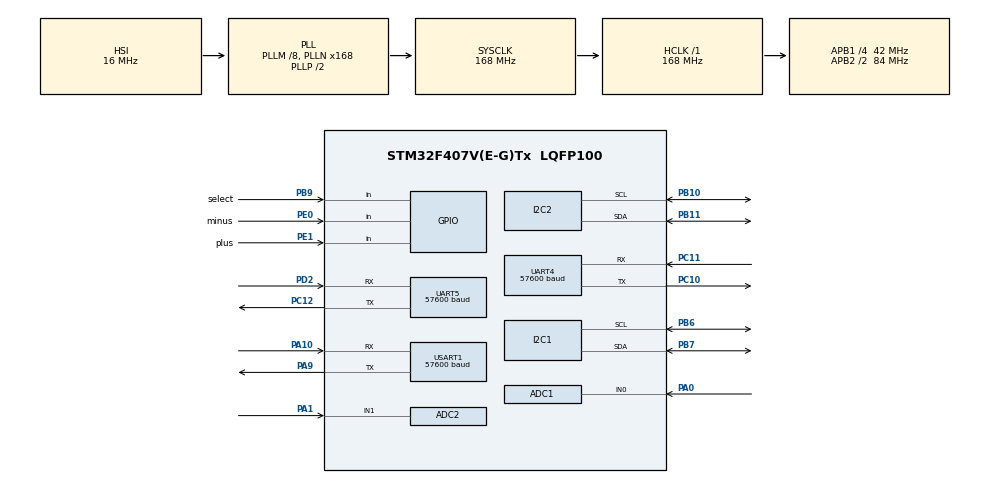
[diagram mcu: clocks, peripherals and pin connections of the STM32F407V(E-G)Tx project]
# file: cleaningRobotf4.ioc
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Mcu.Family=STM32F4
PH0-OSC_IN.Signal=RCC_OSC_IN
RCC.CortexFreq_Value=168000000
PB10.Mode=I2C
ADC1.ContinuousConvMode=ENABLE
ADC2.Channel-0\#ChannelRegularConversion=ADC_CHANNEL_1
USART1.BaudRate=57600
PC10.Signal=UART4_TX
PC12.Signal=UART5_TX
PB11.Signal=I2C2_SDA
RCC.SYSCLKSource=RCC_SYSCLKSOURCE_PLLCLK
ProjectManager.StackSize=0x400
VP_FREERTOS_VS_CMSIS_V2.Mode=CMSIS_V2
NVIC.UART5_IRQn=true\:5\:0\:false\:false\:true\:true\:true\:true
UART4.BaudRate=57600
RCC.HCLKFreq_Value=168000000
RCC.APB2TimFreq_Value=168000000
PB6.Signal=I2C1_SCL
PB6.Mode=I2C
PE1.Signal=GPIO_Input
RCC.AHBFreq_Value=168000000
PH0-OSC_IN.Mode=HSE-External-Oscillator
ADC1.Channel-0\#ChannelRegularConversion=ADC_CHANNEL_VREFINT
RCC.HSE_VALUE=8000000
ADC1.ScanConvMode=ENABLE
VP_ADC1_Vref_Input.Mode=IN-Vrefint
PA14.Mode=Serial_Wire
VP_SYS_VS_tim1.Mode=TIM1
NVIC.TIM2_IRQn=true\:5\:0\:false\:false\:true\:true\:true\:true
PB7.Signal=I2C1_SDA
SH.ADCx_IN0.0=ADC1_IN0,IN0
ADC1.SamplingTime-0\#ChannelRegularConversion=ADC_SAMPLETIME_3CYCLES
PH1-OSC_OUT.Mode=HSE-External-Oscillator
PB9.Signal=GPIO_Input
Mcu.Package=LQFP100
TIM2.Prescaler=1
NVIC.TimeBase=TIM1_UP_TIM10_IRQn
NVIC.TimeBaseIP=TIM1
PA10.Signal=USART1_RX
PB9.GPIO_PuPd=GPIO_PULLUP
ADC2.SamplingTime-0\#ChannelRegularConversion=ADC_SAMPLETIME_15CYCLES
PC11.Mode=Asynchronous
PE0.GPIO_Label=minus
RCC.APB2CLKDivider=RCC_HCLK_DIV2
SH.ADCx_IN1.0=ADC2_IN1,IN1
RCC.APB1TimFreq_Value=84000000
UART5.BaudRate=57600
ADC2.Rank-0\#ChannelRegularConversion=1
NVIC.UART4_IRQn=true\:5\:0\:false\:false\:true\:true\:true\:true
PE0.GPIO_PuPd=GPIO_PULLUP
ADC2.ClockPrescaler=ADC_CLOCK_SYNC_PCLK_DIV8
FREERTOS.Tasks01=defaultTask,24,128,StartDefaultTask,Default,NULL,Dynamic,NULL,NULL
ADC1.Rank-0\#ChannelRegularConversion=1
PB9.GPIO_Label=select
PA10.Mode=Asynchronous
PC11.Signal=UART4_RX
PC10.Mode=Asynchronous
PE1.GPIO_PuPd=GPIO_PULLUP
UART5.VirtualMode=Asynchronous
RCC.APB1CLKDivider=RCC_HCLK_DIV4
UART4.VirtualMode=Asynchronous
PA0-WKUP.Signal=ADCx_IN0
PA13.Signal=SYS_JTMS-SWDIO
PA9.Mode=Asynchronous
PB11.Mode=I2C
ADC2.ContinuousConvMode=ENABLE
ProjectManager.TargetToolchain=STM32CubeIDE
PA9.Signal=USART1_TX
ADC1.Channel-1\#ChannelRegularConversion=ADC_CHANNEL_0
RCC.LSE_VALUE=32768
PA1.Signal=ADCx_IN1
PB10.Signal=I2C2_SCL
PD2.Mode=Asynchronous
PC12.Mode=Asynchronous
board=custom
RCC.VCOOutputFreq_Value=336000000
PE1.GPIO_Label=plus
RCC.APB2Freq_Value=84000000
VP_TIM2_VS_ClockSourceINT.Mode=Internal
PH1-OSC_OUT.Signal=RCC_OSC_OUT
TIM2.Period=41999
ADC1.NbrOfConversion=2
PA13.Mode=Serial_Wire
Mcu.Name=STM32F407V(E-G)Tx
PE0.Signal=GPIO_Input
RCC.48MHZClocksFreq_Value=84000000
ADC1.SamplingTime-1\#ChannelRegularConversion=ADC_SAMPLETIME_15CYCLES
RCC.SYSCLKFreq_VALUE=168000000
ADC1.master=1
ADC2.NbrOfConversionFlag=1
USART1.VirtualMode=VM_ASYNC
ADC1.Rank-1\#ChannelRegularConversion=2
PB7.Mode=I2C
PA14.Signal=SYS_JTCK-SWCLK
ProjectManager.HeapSize=0x200
NVIC.TIM1_UP_TIM10_IRQn=true\:0\:0\:false\:false\:true\:false\:false\:true
RCC.HSI_VALUE=16000000
NVIC.PriorityGroup=NVIC_PRIORITYGROUP_4
ADC1.NbrOfConversionFlag=1
RCC.PLLM=8
RCC.PLLN=168
PD2.Signal=UART5_RX
RCC.APB1Freq_Value=42000000
ADC1.ClockPrescaler=ADC_CLOCK_SYNC_PCLK_DIV8

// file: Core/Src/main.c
/* USER CODE BEGIN Header */
/**
  ******************************************************************************
  * @file           : main.c
  * @brief          : Main program body
  ******************************************************************************
  * @attention
  *
  * <h2><center>&copy; Copyright (c) 2021 STMicroelectronics.
  * All rights reserved.</center></h2>
  *
  * This software component is licensed by ST under BSD 3-Clause license,
  * the "License"; You may not use this file except in compliance with the
  * License. You may obtain a copy of the License at:
  *                        opensource.org/licenses/BSD-3-Clause
  *
  ******************************************************************************
  */
/* USER CODE END Header */
#include "main.h"
#include "cmsis_os.h"

/* USER CODE BEGIN Includes */

#include "taskManagerInterface.h"
/* USER CODE END Includes */

ADC_HandleTypeDef hadc1;
ADC_HandleTypeDef hadc2;

I2C_HandleTypeDef hi2c1;
I2C_HandleTypeDef hi2c2;

TIM_HandleTypeDef htim2;

UART_HandleTypeDef huart4;
UART_HandleTypeDef huart5;
UART_HandleTypeDef huart1;

/* Definitions for defaultTask */
osThreadId_t defaultTaskHandle;
const osThreadAttr_t defaultTask_attributes = {
  .name = "defaultTask",
  .priority = (osPriority_t) osPriorityNormal,
  .stack_size = 128 * 4
};

void SystemClock_Config(void);
static void MX_GPIO_Init(void);
static void MX_ADC1_Init(void);
static void MX_ADC2_Init(void);
static void MX_I2C1_Init(void);
static void MX_TIM2_Init(void);
static void MX_UART4_Init(void);
static void MX_UART5_Init(void);
static void MX_USART1_UART_Init(void);
static void MX_I2C2_Init(void);
void StartDefaultTask(void *argument);

int main(void)
{

  /* MCU Configuration--------------------------------------------------------*/

  /* Reset of all peripherals, Initializes the Flash interface and the Systick. */
  HAL_Init();

  /* Configure the system clock */
  SystemClock_Config();

  /* Initialize all configured peripherals */
  MX_GPIO_Init();
  MX_ADC1_Init();
  MX_ADC2_Init();
  MX_I2C1_Init();
  MX_TIM2_Init();
  MX_UART4_Init();
  MX_UART5_Init();
  MX_USART1_UART_Init();
  MX_I2C2_Init();
  /* USER CODE BEGIN 2 */
  tasks_init();
  /* USER CODE END 2 */

  /* Init scheduler */
  osKernelInitialize();

  /* Create the thread(s) */
  /* creation of defaultTask */
  defaultTaskHandle = osThreadNew(StartDefaultTask, NULL, &defaultTask_attributes);

  /* Start scheduler */
  osKernelStart();

  /* We should never get here as control is now taken by the scheduler */
  /* Infinite loop */
  while (1)
  {

  }
}

void SystemClock_Config(void)
{
  RCC_OscInitTypeDef RCC_OscInitStruct = {0};
  RCC_ClkInitTypeDef RCC_ClkInitStruct = {0};

  /** Configure the main internal regulator output voltage
  */
  __HAL_RCC_PWR_CLK_ENABLE();
  __HAL_PWR_VOLTAGESCALING_CONFIG(PWR_REGULATOR_VOLTAGE_SCALE1);
  /** Initializes the RCC Oscillators according to the specified parameters
  * in the RCC_OscInitTypeDef structure.
  */
  RCC_OscInitStruct.OscillatorType = RCC_OSCILLATORTYPE_HSI;
  RCC_OscInitStruct.HSIState = RCC_HSI_ON;
  RCC_OscInitStruct.HSICalibrationValue = RCC_HSICALIBRATION_DEFAULT;
  RCC_OscInitStruct.PLL.PLLState = RCC_PLL_ON;
  RCC_OscInitStruct.PLL.PLLSource = RCC_PLLSOURCE_HSI;
  RCC_OscInitStruct.PLL.PLLM = 8;
  RCC_OscInitStruct.PLL.PLLN = 168;
  RCC_OscInitStruct.PLL.PLLP = RCC_PLLP_DIV2;
  RCC_OscInitStruct.PLL.PLLQ = 4;
  if (HAL_RCC_OscConfig(&RCC_OscInitStruct) != HAL_OK)
  {
    Error_Handler();
  }
  /** Initializes the CPU, AHB and APB buses clocks
  */
  RCC_ClkInitStruct.ClockType = RCC_CLOCKTYPE_HCLK|RCC_CLOCKTYPE_SYSCLK
                              |RCC_CLOCKTYPE_PCLK1|RCC_CLOCKTYPE_PCLK2;
  RCC_ClkInitStruct.SYSCLKSource = RCC_SYSCLKSOURCE_PLLCLK;
  RCC_ClkInitStruct.AHBCLKDivider = RCC_SYSCLK_DIV1;
  RCC_ClkInitStruct.APB1CLKDivider = RCC_HCLK_DIV4;
  RCC_ClkInitStruct.APB2CLKDivider = RCC_HCLK_DIV2;

  if (HAL_RCC_ClockConfig(&RCC_ClkInitStruct, FLASH_LATENCY_5) != HAL_OK)
  {
    Error_Handler();
  }
}

static void MX_ADC1_Init(void)
{

  ADC_ChannelConfTypeDef sConfig = {0};

  /** Configure the global features of the ADC (Clock, Resolution, Data Alignment and number of conversion)
  */
  hadc1.Instance = ADC1;
  hadc1.Init.ClockPrescaler = ADC_CLOCK_SYNC_PCLK_DIV8;
  hadc1.Init.Resolution = ADC_RESOLUTION_12B;
  hadc1.Init.ScanConvMode = ENABLE;
  hadc1.Init.ContinuousConvMode = ENABLE;
  hadc1.Init.DiscontinuousConvMode = DISABLE;
  hadc1.Init.ExternalTrigConvEdge = ADC_EXTERNALTRIGCONVEDGE_NONE;
  hadc1.Init.ExternalTrigConv = ADC_SOFTWARE_START;
  hadc1.Init.DataAlign = ADC_DATAALIGN_RIGHT;
  hadc1.Init.NbrOfConversion = 2;
  hadc1.Init.DMAContinuousRequests = DISABLE;
  hadc1.Init.EOCSelection = ADC_EOC_SINGLE_CONV;
  if (HAL_ADC_Init(&hadc1) != HAL_OK)
  {
    Error_Handler();
  }
  /** Configure for the selected ADC regular channel its corresponding rank in the sequencer and its sample time.
  */
  sConfig.Channel = ADC_CHANNEL_VREFINT;
  sConfig.Rank = 1;
  sConfig.SamplingTime = ADC_SAMPLETIME_3CYCLES;
  if (HAL_ADC_ConfigChannel(&hadc1, &sConfig) != HAL_OK)
  {
    Error_Handler();
  }
  /** Configure for the selected ADC regular channel its corresponding rank in the sequencer and its sample time.
  */
  sConfig.Channel = ADC_CHANNEL_0;
  sConfig.Rank = 2;
  sConfig.SamplingTime = ADC_SAMPLETIME_3CYCLES;
  if (HAL_ADC_ConfigChannel(&hadc1, &sConfig) != HAL_OK)
  {
    Error_Handler();
  }

}

static void MX_ADC2_Init(void)
{

  ADC_ChannelConfTypeDef sConfig = {0};

  /** Configure the global features of the ADC (Clock, Resolution, Data Alignment and number of conversion)
  */
  hadc2.Instance = ADC2;
  hadc2.Init.ClockPrescaler = ADC_CLOCK_SYNC_PCLK_DIV8;
  hadc2.Init.Resolution = ADC_RESOLUTION_12B;
  hadc2.Init.ScanConvMode = DISABLE;
  hadc2.Init.ContinuousConvMode = ENABLE;
  hadc2.Init.DiscontinuousConvMode = DISABLE;
  hadc2.Init.ExternalTrigConvEdge = ADC_EXTERNALTRIGCONVEDGE_NONE;
  hadc2.Init.ExternalTrigConv = ADC_SOFTWARE_START;
  hadc2.Init.DataAlign = ADC_DATAALIGN_RIGHT;
  hadc2.Init.NbrOfConversion = 1;
  hadc2.Init.DMAContinuousRequests = DISABLE;
  hadc2.Init.EOCSelection = ADC_EOC_SINGLE_CONV;
  if (HAL_ADC_Init(&hadc2) != HAL_OK)
  {
    Error_Handler();
  }
  /** Configure for the selected ADC regular channel its corresponding rank in the sequencer and its sample time.
  */
  sConfig.Channel = ADC_CHANNEL_1;
  sConfig.Rank = 1;
  sConfig.SamplingTime = ADC_SAMPLETIME_3CYCLES;
  if (HAL_ADC_ConfigChannel(&hadc2, &sConfig) != HAL_OK)
  {
    Error_Handler();
  }

}

static void MX_I2C1_Init(void)
{

  hi2c1.Instance = I2C1;
  hi2c1.Init.ClockSpeed = 100000;
  hi2c1.Init.DutyCycle = I2C_DUTYCYCLE_2;
  hi2c1.Init.OwnAddress1 = 0;
  hi2c1.Init.AddressingMode = I2C_ADDRESSINGMODE_7BIT;
  hi2c1.Init.DualAddressMode = I2C_DUALADDRESS_DISABLE;
  hi2c1.Init.OwnAddress2 = 0;
  hi2c1.Init.GeneralCallMode = I2C_GENERALCALL_DISABLE;
  hi2c1.Init.NoStretchMode = I2C_NOSTRETCH_DISABLE;
  if (HAL_I2C_Init(&hi2c1) != HAL_OK)
  {
    Error_Handler();
  }

}

static void MX_I2C2_Init(void)
{

  hi2c2.Instance = I2C2;
  hi2c2.Init.ClockSpeed = 100000;
  hi2c2.Init.DutyCycle = I2C_DUTYCYCLE_2;
  hi2c2.Init.OwnAddress1 = 0;
  hi2c2.Init.AddressingMode = I2C_ADDRESSINGMODE_7BIT;
  hi2c2.Init.DualAddressMode = I2C_DUALADDRESS_DISABLE;
  hi2c2.Init.OwnAddress2 = 0;
  hi2c2.Init.GeneralCallMode = I2C_GENERALCALL_DISABLE;
  hi2c2.Init.NoStretchMode = I2C_NOSTRETCH_DISABLE;
  if (HAL_I2C_Init(&hi2c2) != HAL_OK)
  {
    Error_Handler();
  }

}

static void MX_TIM2_Init(void)
{

  TIM_ClockConfigTypeDef sClockSourceConfig = {0};
  TIM_MasterConfigTypeDef sMasterConfig = {0};

  htim2.Instance = TIM2;
  htim2.Init.Prescaler = 1;
  htim2.Init.CounterMode = TIM_COUNTERMODE_UP;
  htim2.Init.Period = 41999;
  htim2.Init.ClockDivision = TIM_CLOCKDIVISION_DIV1;
  htim2.Init.AutoReloadPreload = TIM_AUTORELOAD_PRELOAD_DISABLE;
  if (HAL_TIM_Base_Init(&htim2) != HAL_OK)
  {
    Error_Handler();
  }
  sClockSourceConfig.ClockSource = TIM_CLOCKSOURCE_INTERNAL;
  if (HAL_TIM_ConfigClockSource(&htim2, &sClockSourceConfig) != HAL_OK)
  {
    Error_Handler();
  }
  sMasterConfig.MasterOutputTrigger = TIM_TRGO_RESET;
  sMasterConfig.MasterSlaveMode = TIM_MASTERSLAVEMODE_DISABLE;
  if (HAL_TIMEx_MasterConfigSynchronization(&htim2, &sMasterConfig) != HAL_OK)
  {
    Error_Handler();
  }

}

static void MX_UART4_Init(void)
{

  huart4.Instance = UART4;
  huart4.Init.BaudRate = 57600;
  huart4.Init.WordLength = UART_WORDLENGTH_8B;
  huart4.Init.StopBits = UART_STOPBITS_1;
  huart4.Init.Parity = UART_PARITY_NONE;
  huart4.Init.Mode = UART_MODE_TX_RX;
  huart4.Init.HwFlowCtl = UART_HWCONTROL_NONE;
  huart4.Init.OverSampling = UART_OVERSAMPLING_16;
  if (HAL_UART_Init(&huart4) != HAL_OK)
  {
    Error_Handler();
  }

}

static void MX_UART5_Init(void)
{

  huart5.Instance = UART5;
  huart5.Init.BaudRate = 57600;
  huart5.Init.WordLength = UART_WORDLENGTH_8B;
  huart5.Init.StopBits = UART_STOPBITS_1;
  huart5.Init.Parity = UART_PARITY_NONE;
  huart5.Init.Mode = UART_MODE_TX_RX;
  huart5.Init.HwFlowCtl = UART_HWCONTROL_NONE;
  huart5.Init.OverSampling = UART_OVERSAMPLING_16;
  if (HAL_UART_Init(&huart5) != HAL_OK)
  {
    Error_Handler();
  }

}

static void MX_USART1_UART_Init(void)
{

  huart1.Instance = USART1;
  huart1.Init.BaudRate = 57600;
  huart1.Init.WordLength = UART_WORDLENGTH_8B;
  huart1.Init.StopBits = UART_STOPBITS_1;
  huart1.Init.Parity = UART_PARITY_NONE;
  huart1.Init.Mode = UART_MODE_TX_RX;
  huart1.Init.HwFlowCtl = UART_HWCONTROL_NONE;
  huart1.Init.OverSampling = UART_OVERSAMPLING_16;
  if (HAL_UART_Init(&huart1) != HAL_OK)
  {
    Error_Handler();
  }

}

static void MX_GPIO_Init(void)
{
  GPIO_InitTypeDef GPIO_InitStruct = {0};

  /* GPIO Ports Clock Enable */
  __HAL_RCC_GPIOH_CLK_ENABLE();
  __HAL_RCC_GPIOA_CLK_ENABLE();
  __HAL_RCC_GPIOB_CLK_ENABLE();
  __HAL_RCC_GPIOC_CLK_ENABLE();
  __HAL_RCC_GPIOD_CLK_ENABLE();
  __HAL_RCC_GPIOE_CLK_ENABLE();

  /*Configure GPIO pin : select_Pin */
  GPIO_InitStruct.Pin = select_Pin;
  GPIO_InitStruct.Mode = GPIO_MODE_INPUT;
  GPIO_InitStruct.Pull = GPIO_PULLUP;
  HAL_GPIO_Init(select_GPIO_Port, &GPIO_InitStruct);

  /*Configure GPIO pins : minus_Pin plus_Pin */
  GPIO_InitStruct.Pin = minus_Pin|plus_Pin;
  GPIO_InitStruct.Mode = GPIO_MODE_INPUT;
  GPIO_InitStruct.Pull = GPIO_PULLUP;
  HAL_GPIO_Init(GPIOE, &GPIO_InitStruct);

}

void StartDefaultTask(void *argument)
{
  for(;;)
  {
    osDelay(1);
  }
}

 /**
  * @brief  Period elapsed callback in non blocking mode
  * @note   This function is called  when TIM1 interrupt took place, inside
  * HAL_TIM_IRQHandler(). It makes a direct call to HAL_IncTick() to increment
  * a global variable "uwTick" used as application time base.
  * @param  htim : TIM handle
  * @retval None
  */
void HAL_TIM_PeriodElapsedCallback(TIM_HandleTypeDef *htim)
{
  if (htim->Instance == TIM1) {
    HAL_IncTick();
  }
}

void Error_Handler(void)
{
  __disable_irq();
  while (1)
  {
  }
}

/************************ (C) COPYRIGHT STMicroelectronics *****END OF FILE****/
